VERSION ""

NS_ :

BS_:

BU_: DTS_Tester DTS_Boards

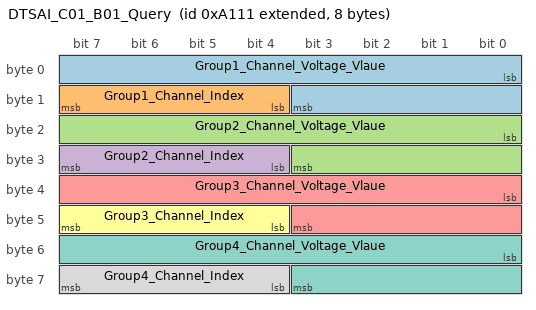
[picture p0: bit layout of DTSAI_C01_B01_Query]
BO_ 2147524881 DTSAI_C01_B01_Query: 8 DTS_Boards
 SG_ Group1_Channel_Voltage_Vlaue : 0|12@1+ (0.0040283203125,0) [0|0] "V" Vector__XXX
 SG_ Group1_Channel_Index : 15|4@0+ (1,0) [0|0] "" Vector__XXX
 SG_ Group2_Channel_Voltage_Vlaue : 16|12@1+ (0.0040283203125,0) [0|0] "V" Vector__XXX
 SG_ Group2_Channel_Index : 31|4@0+ (1,0) [0|0] "" Vector__XXX
 SG_ Group3_Channel_Voltage_Vlaue : 32|12@1+ (0.0040283203125,0) [0|0] "V" Vector__XXX
 SG_ Group3_Channel_Index : 47|4@0+ (1,0) [0|0] "" Vector__XXX
 SG_ Group4_Channel_Voltage_Vlaue : 48|12@1+ (0.0040283203125,0) [0|0] "V" Vector__XXX
 SG_ Group4_Channel_Index : 63|4@0+ (1,0) [0|0] "" Vector__XXX

BA_DEF_  "BusType" STRING ;
BA_DEF_DEF_  "BusType" "CAN";
